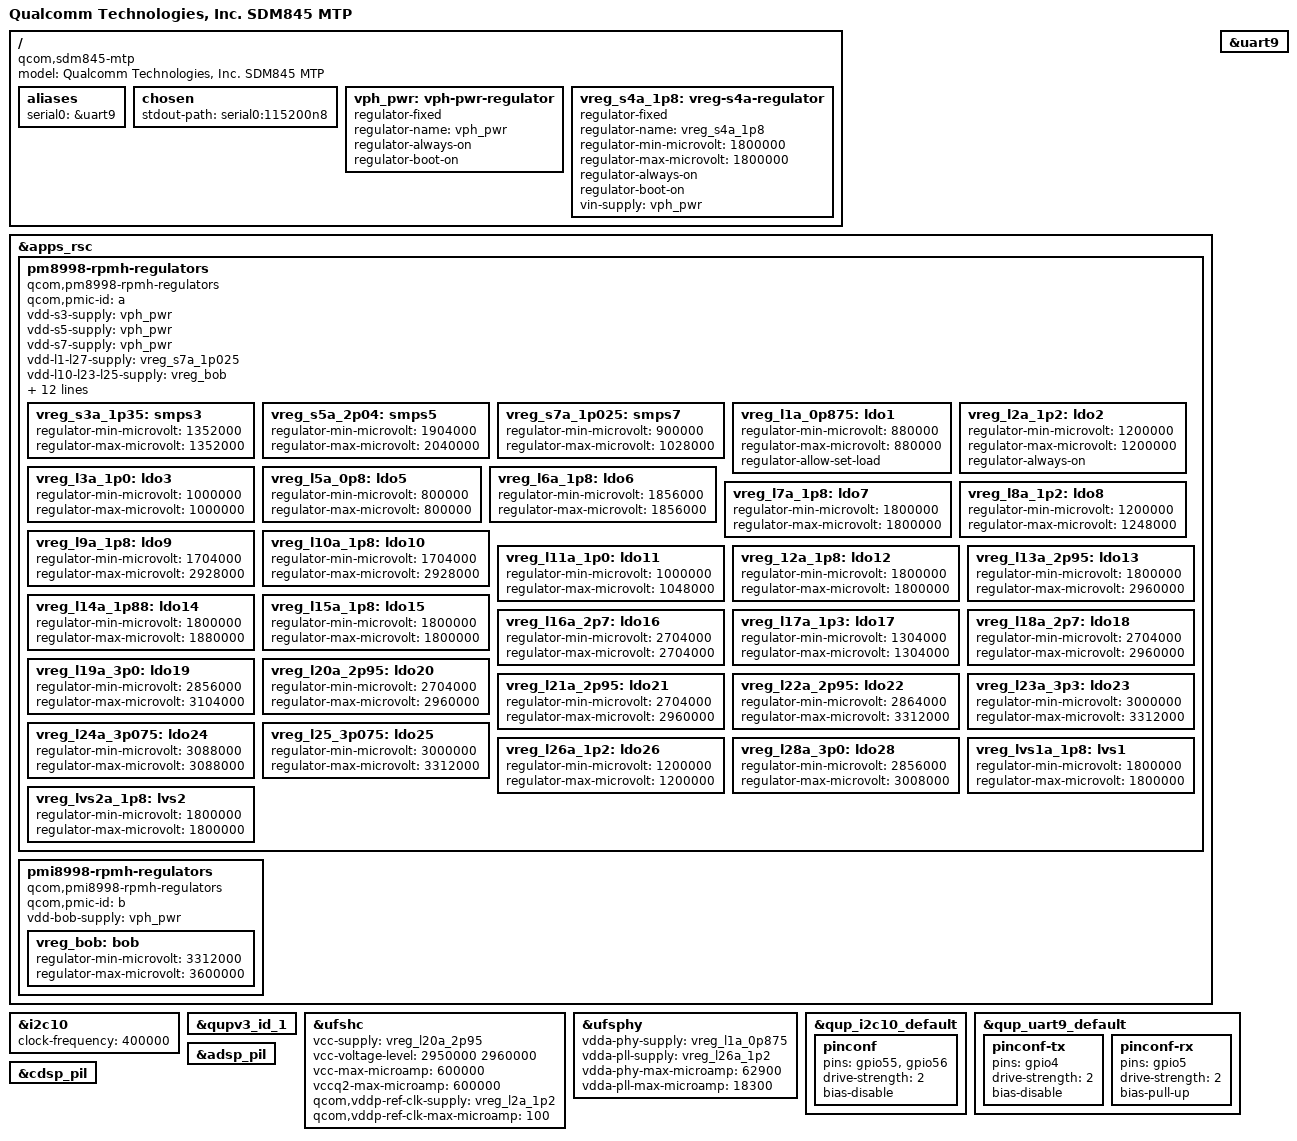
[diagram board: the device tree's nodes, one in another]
// SPDX-License-Identifier: GPL-2.0
/*
 * SDM845 MTP board device tree source
 *
 * Copyright (c) 2018, The Linux Foundation. All rights reserved.
 */

/dts-v1/;

#include <dt-bindings/regulator/qcom,rpmh-regulator.h>
#include "sdm845.dtsi"

/ {
	model = "Qualcomm Technologies, Inc. SDM845 MTP";
	compatible = "qcom,sdm845-mtp";

	aliases {
		serial0 = &uart9;
	};

	chosen {
		stdout-path = "serial0:115200n8";
	};

	vph_pwr: vph-pwr-regulator {
		compatible = "regulator-fixed";
		regulator-name = "vph_pwr";
		regulator-always-on;
		regulator-boot-on;
	};

	/* S4 is always-on 1.8V and not controllable through RPMh */
	vreg_s4a_1p8: vreg-s4a-regulator {
		compatible = "regulator-fixed";
		regulator-name = "vreg_s4a_1p8";

		regulator-min-microvolt = <1800000>;
		regulator-max-microvolt = <1800000>;

		regulator-always-on;
		regulator-boot-on;

		vin-supply = <&vph_pwr>;
	};
};

&apps_rsc {
	pm8998-rpmh-regulators {
		compatible = "qcom,pm8998-rpmh-regulators";
		qcom,pmic-id = "a";

		vdd-s3-supply = <&vph_pwr>;
		vdd-s5-supply = <&vph_pwr>;
		vdd-s7-supply = <&vph_pwr>;
		vdd-l1-l27-supply = <&vreg_s7a_1p025>;
		vdd-l10-l23-l25-supply = <&vreg_bob>;
		vdd-l13-l19-l21-supply = <&vreg_bob>;
		vdd-l16-l28-supply = <&vreg_bob>;
		vdd-l18-l22-supply = <&vreg_bob>;
		vdd-l2-l8-l17-supply = <&vreg_s3a_1p35>;
		vdd-l20-l24-supply = <&vreg_bob>;
		vdd-l26-supply = <&vreg_s3a_1p35>;
		vdd-l3-l11-supply = <&vreg_s7a_1p025>;
		vdd-l4-l5-supply = <&vreg_s7a_1p025>;
		vdd-l6-supply = <&vph_pwr>;
		vdd-l7-l12-l14-l15-supply = <&vreg_s5a_2p04>;
		vdd-l9-supply = <&vreg_bob>;
		vin-lvs-1-2-supply = <&vreg_s4a_1p8>;

		vreg_s3a_1p35: smps3 {
			regulator-min-microvolt = <1352000>;
			regulator-max-microvolt = <1352000>;
		};

		vreg_s5a_2p04: smps5 {
			regulator-min-microvolt = <1904000>;
			regulator-max-microvolt = <2040000>;
		};

		vreg_s7a_1p025: smps7 {
			regulator-min-microvolt = <900000>;
			regulator-max-microvolt = <1028000>;
		};

		vreg_l1a_0p875: ldo1 {
			regulator-min-microvolt = <880000>;
			regulator-max-microvolt = <880000>;
			regulator-allow-set-load;
		};

		vreg_l2a_1p2: ldo2 {
			regulator-min-microvolt = <1200000>;
			regulator-max-microvolt = <1200000>;
			regulator-always-on;
		};

		vreg_l3a_1p0: ldo3 {
			regulator-min-microvolt = <1000000>;
			regulator-max-microvolt = <1000000>;
		};

		vreg_l5a_0p8: ldo5 {
			regulator-min-microvolt = <800000>;
			regulator-max-microvolt = <800000>;
		};

		vreg_l6a_1p8: ldo6 {
			regulator-min-microvolt = <1856000>;
			regulator-max-microvolt = <1856000>;
		};

		vreg_l7a_1p8: ldo7 {
			regulator-min-microvolt = <1800000>;
			regulator-max-microvolt = <1800000>;
		};

		vreg_l8a_1p2: ldo8 {
			 regulator-min-microvolt = <1200000>;
			 regulator-max-microvolt = <1248000>;
		};

		vreg_l9a_1p8: ldo9 {
			regulator-min-microvolt = <1704000>;
			regulator-max-microvolt = <2928000>;
		};

		vreg_l10a_1p8: ldo10 {
			regulator-min-microvolt = <1704000>;
			regulator-max-microvolt = <2928000>;
		};

		vreg_l11a_1p0: ldo11 {
			regulator-min-microvolt = <1000000>;
			regulator-max-microvolt = <1048000>;
		};

		vreg_12a_1p8: ldo12 {
			regulator-min-microvolt = <1800000>;
			regulator-max-microvolt = <1800000>;
		};

		vreg_l13a_2p95: ldo13 {
			regulator-min-microvolt = <1800000>;
			regulator-max-microvolt = <2960000>;
		};

		vreg_l14a_1p88: ldo14 {
			regulator-min-microvolt = <1800000>;
			regulator-max-microvolt = <1880000>;
		};

		vreg_l15a_1p8: ldo15 {
			regulator-min-microvolt = <1800000>;
			regulator-max-microvolt = <1800000>;
		};

		vreg_l16a_2p7: ldo16 {
			regulator-min-microvolt = <2704000>;
			regulator-max-microvolt = <2704000>;
		};

		vreg_l17a_1p3: ldo17 {
			regulator-min-microvolt = <1304000>;
			regulator-max-microvolt = <1304000>;
		};

		vreg_l18a_2p7: ldo18 {
			regulator-min-microvolt = <2704000>;
			regulator-max-microvolt = <2960000>;
		};

		vreg_l19a_3p0: ldo19 {
			regulator-min-microvolt = <2856000>;
			regulator-max-microvolt = <3104000>;
		};

		vreg_l20a_2p95: ldo20 {
			regulator-min-microvolt = <2704000>;
			regulator-max-microvolt = <2960000>;
		};

		vreg_l21a_2p95: ldo21 {
			regulator-min-microvolt = <2704000>;
			regulator-max-microvolt = <2960000>;
		};

		vreg_l22a_2p95: ldo22 {
			regulator-min-microvolt = <2864000>;
			regulator-max-microvolt = <3312000>;
		};

		vreg_l23a_3p3: ldo23 {
			regulator-min-microvolt = <3000000>;
			regulator-max-microvolt = <3312000>;
		};

		vreg_l24a_3p075: ldo24 {
			regulator-min-microvolt = <3088000>;
			regulator-max-microvolt = <3088000>;
		};

		vreg_l25_3p075: ldo25 {
			regulator-min-microvolt = <3000000>;
			regulator-max-microvolt = <3312000>;
		};

		vreg_l26a_1p2: ldo26 {
			regulator-min-microvolt = <1200000>;
			regulator-max-microvolt = <1200000>;
		};

		vreg_l28a_3p0: ldo28 {
			regulator-min-microvolt = <2856000>;
			regulator-max-microvolt = <3008000>;
		};

		vreg_lvs1a_1p8: lvs1 {
			regulator-min-microvolt = <1800000>;
			regulator-max-microvolt = <1800000>;
		};

		vreg_lvs2a_1p8: lvs2 {
			regulator-min-microvolt = <1800000>;
			regulator-max-microvolt = <1800000>;
		};
	};

	pmi8998-rpmh-regulators {
		compatible = "qcom,pmi8998-rpmh-regulators";
		qcom,pmic-id = "b";

		vdd-bob-supply = <&vph_pwr>;

		vreg_bob: bob {
			regulator-min-microvolt = <3312000>;
			regulator-max-microvolt = <3600000>;
		};
	};
};

&i2c10 {
	status = "okay";
	clock-frequency = <400000>;
};

&qupv3_id_1 {
	status = "okay";
};

&uart9 {
	status = "okay";
};

&ufshc {
	status = "okay";

	vcc-supply = <&vreg_l20a_2p95>;
	vcc-voltage-level = <2950000 2960000>;
	vcc-max-microamp = <600000>;
	vccq2-max-microamp = <600000>;

	qcom,vddp-ref-clk-supply = <&vreg_l2a_1p2>;
	qcom,vddp-ref-clk-max-microamp = <100>;
};

&ufsphy {
	status = "okay";

	vdda-phy-supply = <&vreg_l1a_0p875>; /* 0.88v */
	vdda-pll-supply = <&vreg_l26a_1p2>; /* 1.2v */
	vdda-phy-max-microamp = <62900>;
	vdda-pll-max-microamp = <18300>;
};

/* PINCTRL - additions to nodes defined in sdm845.dtsi */

&qup_i2c10_default {
	pinconf {
		pins = "gpio55", "gpio56";
		drive-strength = <2>;
		bias-disable;
	};
};

&qup_uart9_default {
	pinconf-tx {
		pins = "gpio4";
		drive-strength = <2>;
		bias-disable;
	};

	pinconf-rx {
		pins = "gpio5";
		drive-strength = <2>;
		bias-pull-up;
	};
};

&adsp_pil {
	status = "okay";
};

&cdsp_pil {
	status = "okay";
};
